# liliumFP1_application register map
Vendor: Nordic Semiconductor; Series: liliumFP1; File version: 1
CPU: CM33 r0p4, little endian, MPU, FPU, 3 interrupt priority bits, 480 interrupts
Registers are 32-bit, read-write, reset 0x0 unless marked. A register's access mark holds for its fields unless they carry their own. Offsets are from the block's base; [hi:lo] are bit positions; lines under a group give offsets from that group; {n}, {i} and the like mark numbered series; 'fields as' and 'values as' point back to an identical list.

## GLOBAL_PWM120_NS — Pulse width modulation unit 0
Base 0x4F8E4000
Same registers: GLOBAL_PWM130_NS 0x4F9A4000, GLOBAL_PWM131_NS 0x4F9B4000, GLOBAL_PWM132_NS 0x4F9C4000, GLOBAL_PWM133_NS 0x4F9D4000, GLOBAL_PWM120_S 0x5F8E4000, GLOBAL_PWM130_S 0x5F9A4000, GLOBAL_PWM131_S 0x5F9B4000, GLOBAL_PWM132_S 0x5F9C4000, GLOBAL_PWM133_S 0x5F9D4000
0x00 TASKS_START wo — Starts PWM pulse generation with the last loaded values
  [0] TASKS_START
    1=Trigger task
0x04 TASKS_STOP wo — Stops PWM pulse generation on all channels at the end of current PWM period, and stops sequence playback
  [0] TASKS_STOP
    1=Trigger task
{0x8+4i} TASKS_SEQSTART[{i}] (i=0..1) wo — Description collection: Loads the first PWM value on all enabled channels from sequence n, and starts playing that sequence at the rate defined in SEQ[n]REFRESH and/or DECODER.MODE. Causes PWM generation to start if not running. Triggering a SEQSTART[n] task while a sequence is already playing back will gracefully (i.e. glitch-free) abort that sequence at the earliest opportunity and start sequence n.
  [0] TASKS_SEQSTART — Loads the first PWM value on all enabled channels from sequence n, and starts playing that sequence at the rate defined in SEQ[n]REFRESH and/or DECODER.MODE. Causes PWM generation to start if not running. Triggering a SEQSTART[n] task while a sequence is already playing back will gracefully (i.e. glitch-free) abort that sequence at the earliest opportunity and start sequence n.
    1=Trigger task
0x10 TASKS_NEXTSTEP wo — Steps by one value in the current sequence on all enabled channels if DECODER.MODE=NextStep. Does not cause PWM generation to start if not running.
  [0] TASKS_NEXTSTEP
    1=Trigger task
0x14 TASKS_SEQABORT wo — (Gracefully) aborts the playback of the current sequence or the current end delay
  [0] TASKS_SEQABORT
    1=Trigger task
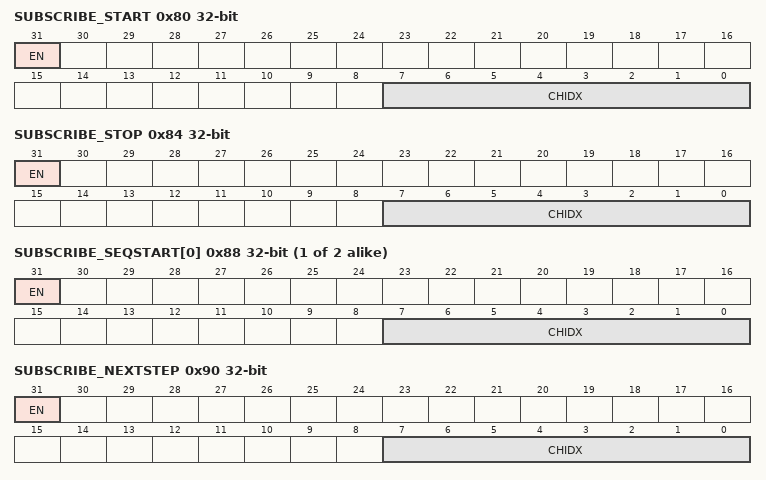
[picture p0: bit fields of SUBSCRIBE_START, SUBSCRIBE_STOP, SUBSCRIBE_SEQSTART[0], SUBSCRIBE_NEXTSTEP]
0x80 SUBSCRIBE_START — Subscribe configuration for task START
  [31] EN
    0=Disabled (Disable subscription); 1=Enabled (Enable subscription)
  [7:0] CHIDX — DPPI channel that task START will subscribe to
0x84 SUBSCRIBE_STOP — Subscribe configuration for task STOP
  [31] EN
    values as SUBSCRIBE_START.EN
  [7:0] CHIDX — DPPI channel that task STOP will subscribe to
{0x88+4i} SUBSCRIBE_SEQSTART[{i}] (i=0..1) — Description collection: Subscribe configuration for task SEQSTART[n]
  [31] EN
    values as SUBSCRIBE_START.EN
  [7:0] CHIDX — DPPI channel that task SEQSTART[n] will subscribe to
0x90 SUBSCRIBE_NEXTSTEP — Subscribe configuration for task NEXTSTEP
  [31] EN
    values as SUBSCRIBE_START.EN
  [7:0] CHIDX — DPPI channel that task NEXTSTEP will subscribe to
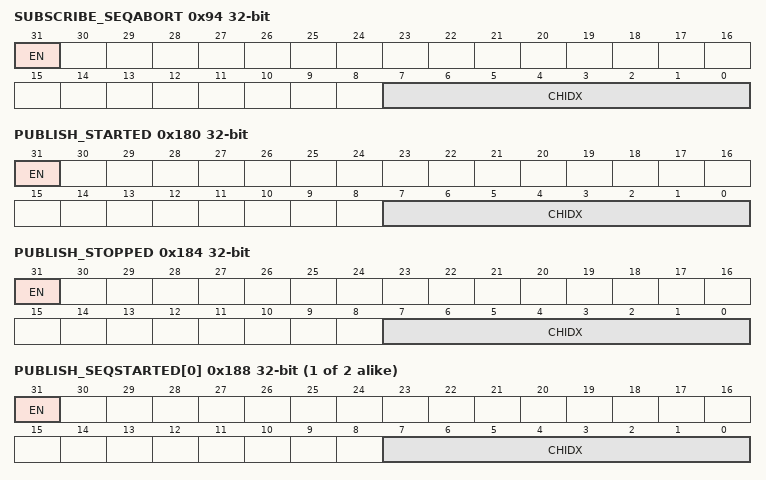
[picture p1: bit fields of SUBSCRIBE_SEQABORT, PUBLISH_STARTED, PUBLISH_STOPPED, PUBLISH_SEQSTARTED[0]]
0x94 SUBSCRIBE_SEQABORT — Subscribe configuration for task SEQABORT
  [31] EN
    values as SUBSCRIBE_START.EN
  [7:0] CHIDX — DPPI channel that task SEQABORT will subscribe to
0x100 EVENTS_STARTED — Response to START task, emitted when the PWM pulse generation starts
  [0] EVENTS_STARTED
    0=NotGenerated (Event not generated); 1=Generated (Event generated)
0x104 EVENTS_STOPPED — Response to STOP task, emitted when PWM pulses are no longer generated
  [0] EVENTS_STOPPED
    values as EVENTS_STARTED.EVENTS_STARTED
{0x108+4i} EVENTS_SEQSTARTED[{i}] (i=0..1) — Description collection: First PWM period started on sequence n
  [0] EVENTS_SEQSTARTED — First PWM period started on sequence n
    values as EVENTS_STARTED.EVENTS_STARTED
{0x110+4i} EVENTS_SEQEND[{i}] (i=0..1) — Description collection: Emitted at end of every sequence n, when last value from RAM has been applied to wave counter
  [0] EVENTS_SEQEND — Emitted at end of every sequence n, when last value from RAM has been applied to wave counter
    values as EVENTS_STARTED.EVENTS_STARTED
0x118 EVENTS_PWMPERIODEND — Emitted at the end of each PWM period
  [0] EVENTS_PWMPERIODEND
    values as EVENTS_STARTED.EVENTS_STARTED
0x11C EVENTS_LOOPSDONE — Concatenated sequences have been played the amount of times defined in LOOP.CNT
  [0] EVENTS_LOOPSDONE
    values as EVENTS_STARTED.EVENTS_STARTED
0x120 EVENTS_RAMUNDERFLOW — Emitted when retrieving from RAM does not complete in time for the PWM module
  [0] EVENTS_RAMUNDERFLOW
    values as EVENTS_STARTED.EVENTS_STARTED
{0x124+4i} EVENTS_DMAREADY[{i}] (i=0..1) — Description collection: Emitted when EasyDMA has retrieved the .PTR and .CNT registers for sequence n (they can be prepared for the next sequence)
  [0] EVENTS_DMAREADY — Emitted when EasyDMA has retrieved the .PTR and .CNT registers for sequence n (they can be prepared for the next sequence)
    values as EVENTS_STARTED.EVENTS_STARTED
{0x12C+4i} EVENTS_DMAEND[{i}] (i=0..1) — Description collection: Emitted when EasyDMA has completed retrieving the values of sequence n from RAM buffer
  [0] EVENTS_DMAEND — Emitted when EasyDMA has completed retrieving the values of sequence n from RAM buffer
    values as EVENTS_STARTED.EVENTS_STARTED
{0x134+4i} EVENTS_BUSERROR[{i}] (i=0..1) — Description collection: This event is generated if an error occurs during the bus transfer. This event is generated on an AHB / AXI error response.
  [0] EVENTS_BUSERROR — This event is generated if an error occurs during the bus transfer. This event is generated on an AHB / AXI error response.
    values as EVENTS_STARTED.EVENTS_STARTED
{0x13C+4i} EVENTS_COMPAREMATCH[{i}] (i=0..3) — Description collection: This event is generated when the compare matches for the compare channel [n].
  [0] EVENTS_COMPAREMATCH — This event is generated when the compare matches for the compare channel [n].
    values as EVENTS_STARTED.EVENTS_STARTED
0x180 PUBLISH_STARTED — Publish configuration for event STARTED
  [31] EN
    0=Disabled (Disable publishing); 1=Enabled (Enable publishing)
  [7:0] CHIDX — DPPI channel that event STARTED will publish to
0x184 PUBLISH_STOPPED — Publish configuration for event STOPPED
  [31] EN
    values as PUBLISH_STARTED.EN
  [7:0] CHIDX — DPPI channel that event STOPPED will publish to
{0x188+4i} PUBLISH_SEQSTARTED[{i}] (i=0..1) — Description collection: Publish configuration for event SEQSTARTED[n]
  [31] EN
    values as PUBLISH_STARTED.EN
  [7:0] CHIDX — DPPI channel that event SEQSTARTED[n] will publish to
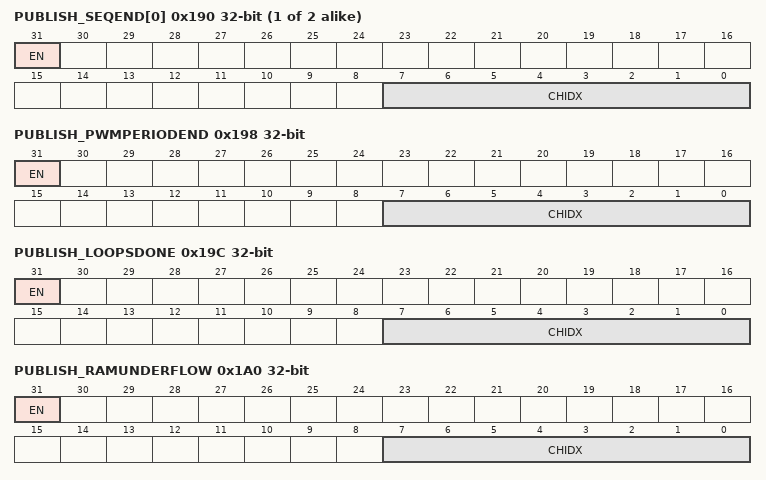
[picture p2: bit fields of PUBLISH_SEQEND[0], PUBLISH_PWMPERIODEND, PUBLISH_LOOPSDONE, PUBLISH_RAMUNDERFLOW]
{0x190+4i} PUBLISH_SEQEND[{i}] (i=0..1) — Description collection: Publish configuration for event SEQEND[n]
  [31] EN
    values as PUBLISH_STARTED.EN
  [7:0] CHIDX — DPPI channel that event SEQEND[n] will publish to
0x198 PUBLISH_PWMPERIODEND — Publish configuration for event PWMPERIODEND
  [31] EN
    values as PUBLISH_STARTED.EN
  [7:0] CHIDX — DPPI channel that event PWMPERIODEND will publish to
0x19C PUBLISH_LOOPSDONE — Publish configuration for event LOOPSDONE
  [31] EN
    values as PUBLISH_STARTED.EN
  [7:0] CHIDX — DPPI channel that event LOOPSDONE will publish to
0x1A0 PUBLISH_RAMUNDERFLOW — Publish configuration for event RAMUNDERFLOW
  [31] EN
    values as PUBLISH_STARTED.EN
  [7:0] CHIDX — DPPI channel that event RAMUNDERFLOW will publish to
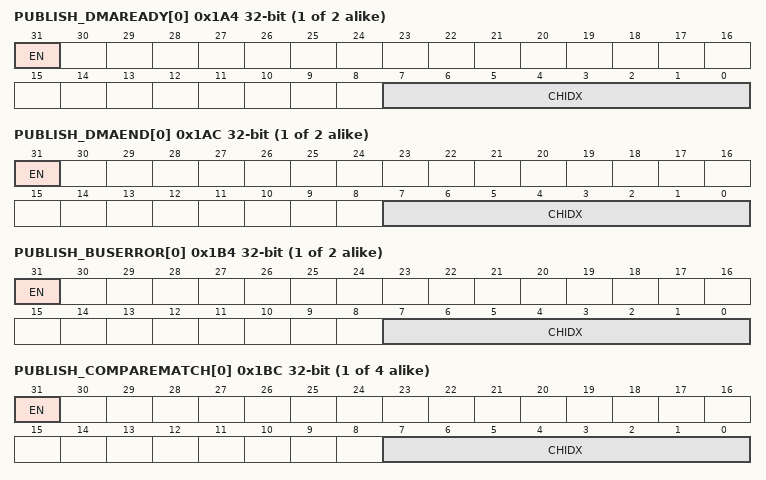
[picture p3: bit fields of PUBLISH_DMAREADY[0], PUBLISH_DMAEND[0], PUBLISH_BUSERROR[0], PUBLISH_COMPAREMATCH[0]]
{0x1A4+4i} PUBLISH_DMAREADY[{i}] (i=0..1) — Description collection: Publish configuration for event DMAREADY[n]
  [31] EN
    values as PUBLISH_STARTED.EN
  [7:0] CHIDX — DPPI channel that event DMAREADY[n] will publish to
{0x1AC+4i} PUBLISH_DMAEND[{i}] (i=0..1) — Description collection: Publish configuration for event DMAEND[n]
  [31] EN
    values as PUBLISH_STARTED.EN
  [7:0] CHIDX — DPPI channel that event DMAEND[n] will publish to
{0x1B4+4i} PUBLISH_BUSERROR[{i}] (i=0..1) — Description collection: Publish configuration for event BUSERROR[n]
  [31] EN
    values as PUBLISH_STARTED.EN
  [7:0] CHIDX — DPPI channel that event BUSERROR[n] will publish to
{0x1BC+4i} PUBLISH_COMPAREMATCH[{i}] (i=0..3) — Description collection: Publish configuration for event COMPAREMATCH[n]
  [31] EN
    values as PUBLISH_STARTED.EN
  [7:0] CHIDX — DPPI channel that event COMPAREMATCH[n] will publish to
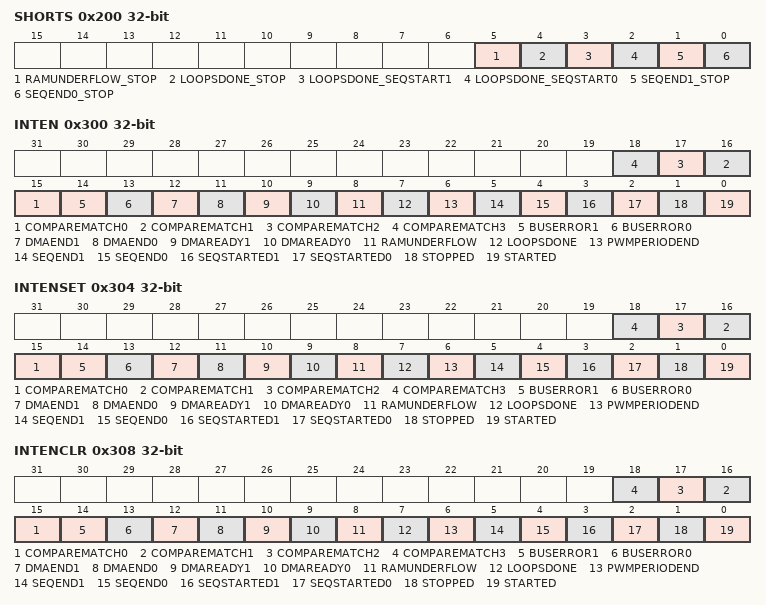
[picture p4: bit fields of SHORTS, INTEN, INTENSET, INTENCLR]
0x200 SHORTS — Shortcuts between local events and tasks
  [all] fields
    0=Disabled (Disable shortcut); 1=Enabled (Enable shortcut)
  [5] RAMUNDERFLOW_STOP — Shortcut between event RAMUNDERFLOW and task STOP
  [4] LOOPSDONE_STOP — Shortcut between event LOOPSDONE and task STOP
  [3] LOOPSDONE_SEQSTART1 — Shortcut between event LOOPSDONE and task SEQSTART[n]
  [2] LOOPSDONE_SEQSTART0 — Shortcut between event LOOPSDONE and task SEQSTART[n]
  [1] SEQEND1_STOP — Shortcut between event SEQEND[n] and task STOP
  [0] SEQEND0_STOP — Shortcut between event SEQEND[n] and task STOP
0x300 INTEN — Enable or disable interrupt
  [all] fields
    0=Disabled; 1=Enabled
  [n+15] COMPAREMATCH{n} (n=0..3) — Enable or disable interrupt for event COMPAREMATCH[{n}]
  [14] BUSERROR1 — Enable or disable interrupt for event BUSERROR[1]
  [13] BUSERROR0 — Enable or disable interrupt for event BUSERROR[0]
  [12] DMAEND1 — Enable or disable interrupt for event DMAEND[1]
  [11] DMAEND0 — Enable or disable interrupt for event DMAEND[0]
  [10] DMAREADY1 — Enable or disable interrupt for event DMAREADY[1]
  [9] DMAREADY0 — Enable or disable interrupt for event DMAREADY[0]
  [8] RAMUNDERFLOW — Enable or disable interrupt for event RAMUNDERFLOW
  [7] LOOPSDONE — Enable or disable interrupt for event LOOPSDONE
  [6] PWMPERIODEND — Enable or disable interrupt for event PWMPERIODEND
  [5] SEQEND1 — Enable or disable interrupt for event SEQEND[1]
  [4] SEQEND0 — Enable or disable interrupt for event SEQEND[0]
  [3] SEQSTARTED1 — Enable or disable interrupt for event SEQSTARTED[1]
  [2] SEQSTARTED0 — Enable or disable interrupt for event SEQSTARTED[0]
  [1] STOPPED — Enable or disable interrupt for event STOPPED
  [0] STARTED — Enable or disable interrupt for event STARTED
0x304 INTENSET — Enable interrupt
  [all] fields
    on read: 0=Disabled (Read: Disabled); 1=Enabled (Read: Enabled) | on write: 1=Set (Enable)
  [n+15] COMPAREMATCH{n} (n=0..3) — Write '1' to enable interrupt for event COMPAREMATCH[{n}]
  [14] BUSERROR1 — Write '1' to enable interrupt for event BUSERROR[1]
  [13] BUSERROR0 — Write '1' to enable interrupt for event BUSERROR[0]
  [12] DMAEND1 — Write '1' to enable interrupt for event DMAEND[1]
  [11] DMAEND0 — Write '1' to enable interrupt for event DMAEND[0]
  [10] DMAREADY1 — Write '1' to enable interrupt for event DMAREADY[1]
  [9] DMAREADY0 — Write '1' to enable interrupt for event DMAREADY[0]
  [8] RAMUNDERFLOW — Write '1' to enable interrupt for event RAMUNDERFLOW
  [7] LOOPSDONE — Write '1' to enable interrupt for event LOOPSDONE
  [6] PWMPERIODEND — Write '1' to enable interrupt for event PWMPERIODEND
  [5] SEQEND1 — Write '1' to enable interrupt for event SEQEND[1]
  [4] SEQEND0 — Write '1' to enable interrupt for event SEQEND[0]
  [3] SEQSTARTED1 — Write '1' to enable interrupt for event SEQSTARTED[1]
  [2] SEQSTARTED0 — Write '1' to enable interrupt for event SEQSTARTED[0]
  [1] STOPPED — Write '1' to enable interrupt for event STOPPED
  [0] STARTED — Write '1' to enable interrupt for event STARTED
0x308 INTENCLR — Disable interrupt
  [all] fields
    on read: 0=Disabled (Read: Disabled); 1=Enabled (Read: Enabled) | on write: 1=Clear (Disable)
  [n+15] COMPAREMATCH{n} (n=0..3) — Write '1' to disable interrupt for event COMPAREMATCH[{n}]
  [14] BUSERROR1 — Write '1' to disable interrupt for event BUSERROR[1]
  [13] BUSERROR0 — Write '1' to disable interrupt for event BUSERROR[0]
  [12] DMAEND1 — Write '1' to disable interrupt for event DMAEND[1]
  [11] DMAEND0 — Write '1' to disable interrupt for event DMAEND[0]
  [10] DMAREADY1 — Write '1' to disable interrupt for event DMAREADY[1]
  [9] DMAREADY0 — Write '1' to disable interrupt for event DMAREADY[0]
  [8] RAMUNDERFLOW — Write '1' to disable interrupt for event RAMUNDERFLOW
  [7] LOOPSDONE — Write '1' to disable interrupt for event LOOPSDONE
  [6] PWMPERIODEND — Write '1' to disable interrupt for event PWMPERIODEND
  [5] SEQEND1 — Write '1' to disable interrupt for event SEQEND[1]
  [4] SEQEND0 — Write '1' to disable interrupt for event SEQEND[0]
  [3] SEQSTARTED1 — Write '1' to disable interrupt for event SEQSTARTED[1]
  [2] SEQSTARTED0 — Write '1' to disable interrupt for event SEQSTARTED[0]
  [1] STOPPED — Write '1' to disable interrupt for event STOPPED
  [0] STARTED — Write '1' to disable interrupt for event STARTED
0x500 ENABLE — PWM module enable register
  [0] ENABLE — Enable or disable PWM module
    0=Disabled; 1=Enabled
0x504 MODE — Selects operating mode of the wave counter
  [0] UPDOWN — Selects up mode or up-and-down mode for the counter
    0=Up (Up counter, edge-aligned PWM duty cycle); 1=Up and down counter, center-aligned PWM duty cycle
0x508 COUNTERTOP reset 0x3FF — Value up to which the pulse generator counter counts
  [14:0] COUNTERTOP — Value up to which the pulse generator counter counts. This register is ignored when DECODER.MODE=WaveForm and only values from RAM are used.
0x50C PRESCALER — Configuration for PWM_CLK
  [2:0] PRESCALER — Prescaler of PWM_CLK
    0=DIV_1 (Divide by 1 (16 MHz)); 1=DIV_2 (Divide by 2 (8 MHz)); 2=DIV_4 (Divide by 4 (4 MHz)); 3=DIV_8 (Divide by 8 (2 MHz)); 4=DIV_16 (Divide by 16 (1 MHz)); 5=DIV_32 (Divide by 32 (500 kHz)); 6=DIV_64 (Divide by 64 (250 kHz)); 7=DIV_128 (Divide by 128 (125 kHz))
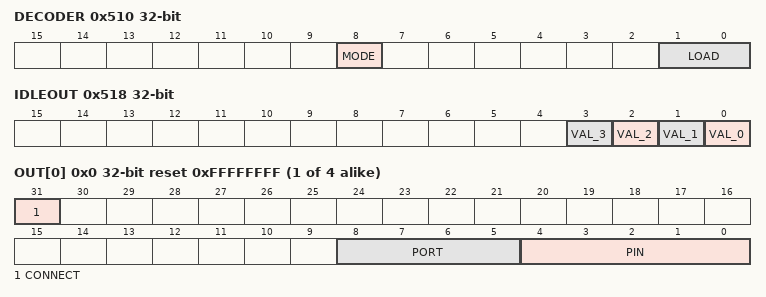
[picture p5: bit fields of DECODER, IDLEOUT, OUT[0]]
0x510 DECODER — Configuration of the decoder
  [8] MODE — Selects source for advancing the active sequence
    0=RefreshCount (SEQ[n].REFRESH is used to determine loading internal compare registers); 1=NEXTSTEP task causes a new value to be loaded to internal compare registers
  [1:0] LOAD — How a sequence is read from RAM and spread to the compare register
    0=Common (1st half word (16-bit) used in all PWM channels 0..3); 1=Grouped (1st half word (16-bit) used in channel 0..1; 2nd word in channel 2..3); 2=Individual (1st half word (16-bit) in ch.0; 2nd in ch.1; ...; 4th in ch.3); 3=WaveForm (1st half word (16-bit) in ch.0; 2nd in ch.1; ...; 4th in COUNTERTOP)
0x514 LOOP — Number of playbacks of a loop
  [15:0] CNT — Number of playbacks of pattern cycles
    0=Disabled (Looping disabled (stop at the end of the sequence))
0x518 IDLEOUT — Configure the output value on the PWM channel during idle
  [n] VAL_{n} (n=0..3) — Idle output value for PWM channel [{n}]
{0x520+0x20*i} SEQ[{i}] (i=0..1) group — Unspecified
  0x00 PTR — Description cluster: Beginning address in RAM of this sequence
    [31:0] PTR — Beginning address in RAM of this sequence
  0x04 CNT — Description cluster: Number of values (duty cycles) in this sequence
    [14:0] CNT — Number of values (duty cycles) in this sequence
      0=Disabled (Sequence is disabled, and shall not be started as it is empty)
  0x08 REFRESH reset 0x1 — Description cluster: Number of additional PWM periods between samples loaded into compare register
    [23:0] CNT — Number of additional PWM periods between samples loaded into compare register (load every REFRESH.CNT+1 PWM periods)
      0=Continuous (Update every PWM period)
  0x0C ENDDELAY — Description cluster: Time added after the sequence
    [23:0] CNT — Time added after the sequence in PWM periods
  0x10 TERMINATEONBUSERROR — Description cluster: Terminate the transaction if a BUSERROR event is detected.
    [0] ENABLE
      0=Disabled; 1=Enabled
  0x14 BUSERRORADDRESS — Description cluster: Address of transaction that generated the last BUSERROR event.
    [31:0] ADDRESS
0x560 PSEL group — Unspecified
  {0x0+4j} OUT[{j}] (j=0..3) reset 0xFFFFFFFF — Description collection: Output pin select for PWM channel n
    [31] CONNECT — Connection
      1=Disconnected; 0=Connected
    [8:5] PORT — Port number
    [4:0] PIN — Pin number
0x570 DMA group — Unspecified
  0x00 SEQA group — Unspecified
    0x00 ENABLE — Register doesn't do anything. Can be written and read, but has no functionality attached.
      [0] ENABLE
        0=DISABLE (Unspecified); 1=ENABLE (Unspecified)
  0x10 SEQB group — Unspecified
    0x00 ENABLE — Register doesn't do anything. Can be written and read, but has no functionality attached.
      [0] ENABLE
        0=DISABLE (Unspecified); 1=ENABLE (Unspecified)
